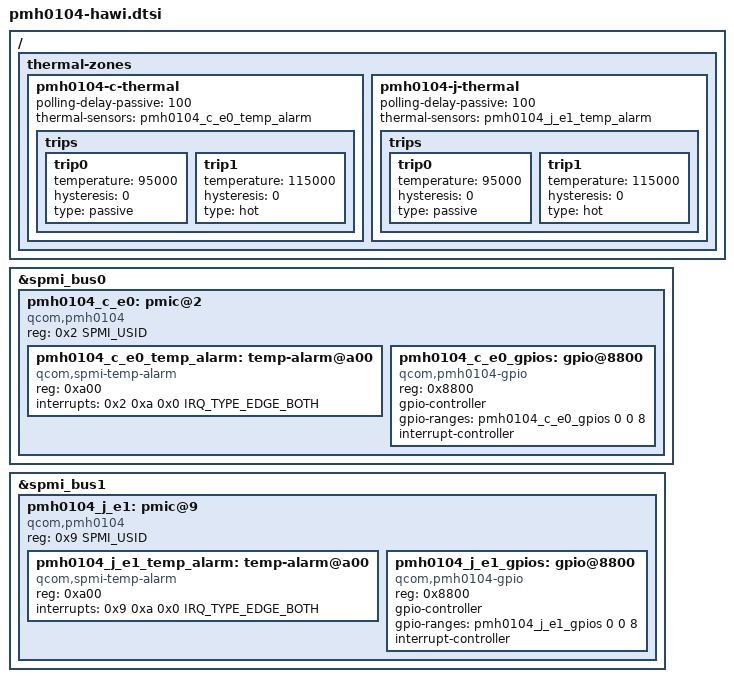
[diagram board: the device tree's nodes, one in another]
// SPDX-License-Identifier: BSD-3-Clause
/*
 * Copyright (c) Qualcomm Technologies, Inc. and/or its subsidiaries.
 */

#include <dt-bindings/interrupt-controller/irq.h>
#include <dt-bindings/spmi/spmi.h>

/ {
	thermal-zones {
		pmh0104-c-thermal {
			polling-delay-passive = <100>;

			thermal-sensors = <&pmh0104_c_e0_temp_alarm>;

			trips {
				trip0 {
					temperature = <95000>;
					hysteresis = <0>;
					type = "passive";
				};

				trip1 {
					temperature = <115000>;
					hysteresis = <0>;
					type = "hot";
				};
			};
		};

		pmh0104-j-thermal {
			polling-delay-passive = <100>;

			thermal-sensors = <&pmh0104_j_e1_temp_alarm>;

			trips {
				trip0 {
					temperature = <95000>;
					hysteresis = <0>;
					type = "passive";
				};

				trip1 {
					temperature = <115000>;
					hysteresis = <0>;
					type = "hot";
				};
			};
		};
	};
};

&spmi_bus0 {
	pmh0104_c_e0: pmic@2 {
		compatible = "qcom,pmh0104", "qcom,spmi-pmic";
		reg = <0x2 SPMI_USID>;
		#address-cells = <1>;
		#size-cells = <0>;

		pmh0104_c_e0_temp_alarm: temp-alarm@a00 {
			compatible = "qcom,spmi-temp-alarm";
			reg = <0xa00>;
			interrupts = <0x2 0xa 0x0 IRQ_TYPE_EDGE_BOTH>;
			#thermal-sensor-cells = <0>;
		};

		pmh0104_c_e0_gpios: gpio@8800 {
			compatible = "qcom,pmh0104-gpio", "qcom,spmi-gpio";
			reg = <0x8800>;
			gpio-controller;
			gpio-ranges = <&pmh0104_c_e0_gpios 0 0 8>;
			#gpio-cells = <2>;
			interrupt-controller;
			#interrupt-cells = <2>;
		};
	};
};

&spmi_bus1 {
	pmh0104_j_e1: pmic@9 {
		compatible = "qcom,pmh0104", "qcom,spmi-pmic";
		reg = <0x9 SPMI_USID>;
		#address-cells = <1>;
		#size-cells = <0>;

		pmh0104_j_e1_temp_alarm: temp-alarm@a00 {
			compatible = "qcom,spmi-temp-alarm";
			reg = <0xa00>;
			interrupts = <0x9 0xa 0x0 IRQ_TYPE_EDGE_BOTH>;
			#thermal-sensor-cells = <0>;
		};

		pmh0104_j_e1_gpios: gpio@8800 {
			compatible = "qcom,pmh0104-gpio", "qcom,spmi-gpio";
			reg = <0x8800>;
			gpio-controller;
			gpio-ranges = <&pmh0104_j_e1_gpios 0 0 8>;
			#gpio-cells = <2>;
			interrupt-controller;
			#interrupt-cells = <2>;
		};
	};
};
